# MSP432E401Y register map
Vendor: Texas Instruments; Series: MSP432E4; File version: 3.200
CPU: CM4 r1p2, little endian, no MPU, FPU, 3 interrupt priority bits
Registers are 32-bit, read-write, no defined reset value unless marked. A register's access mark holds for its fields unless they carry their own. Offsets are from the block's base; [hi:lo] are bit positions.

## SHAMD5_DMA — Register map for SHAMD5 DMA peripheral
Base 0x44030010; register names take the prefix SHAMD5_DMA
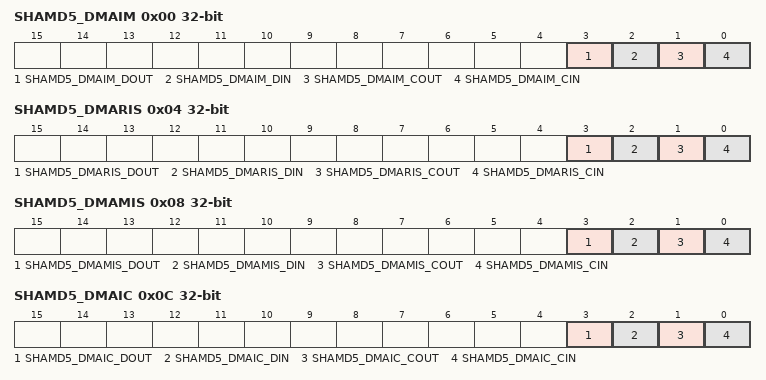
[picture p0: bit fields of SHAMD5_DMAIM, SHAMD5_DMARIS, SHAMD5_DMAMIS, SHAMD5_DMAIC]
0x00 SHAMD5_DMAIM — SHAMD5 DMA Interrupt Mask
  [3] SHAMD5_DMAIM_DOUT — Data Out DMA Done Interrupt Mask
  [2] SHAMD5_DMAIM_DIN — Data In DMA Done Interrupt Mask
  [1] SHAMD5_DMAIM_COUT — Context Out DMA Done Interrupt Mask
  [0] SHAMD5_DMAIM_CIN — Context In DMA Done Interrupt Mask
0x04 SHAMD5_DMARIS — SHAMD5 DMA Raw Interrupt Status
  [3] SHAMD5_DMARIS_DOUT — Data Out DMA Done Raw Interrupt Status
  [2] SHAMD5_DMARIS_DIN — Data In DMA Done Raw Interrupt Status
  [1] SHAMD5_DMARIS_COUT — Context Out DMA Done Raw Interrupt Status
  [0] SHAMD5_DMARIS_CIN — Context In DMA Done Raw Interrupt Status
0x08 SHAMD5_DMAMIS — SHAMD5 DMA Masked Interrupt Status
  [3] SHAMD5_DMAMIS_DOUT — Data Out DMA Done Masked Interrupt Status
  [2] SHAMD5_DMAMIS_DIN — Data In DMA Done Masked Interrupt Status
  [1] SHAMD5_DMAMIS_COUT — Context Out DMA Done Masked Interrupt Status
  [0] SHAMD5_DMAMIS_CIN — Context In DMA Done Masked Interrupt Status
0x0C SHAMD5_DMAIC — SHAMD5 DMA Interrupt Clear
  [3] SHAMD5_DMAIC_DOUT — Data Out DMA Done Interrupt Clear
  [2] SHAMD5_DMAIC_DIN — Data In DMA Done Interrupt Clear
  [1] SHAMD5_DMAIC_COUT — Context Out DMA Done Interrupt Clear
  [0] SHAMD5_DMAIC_CIN — Context In DMA Done Interrupt Clear

## AES_DMA — Register map for AES DMA peripheral
Base 0x44030020; register names take the prefix AES_DMA
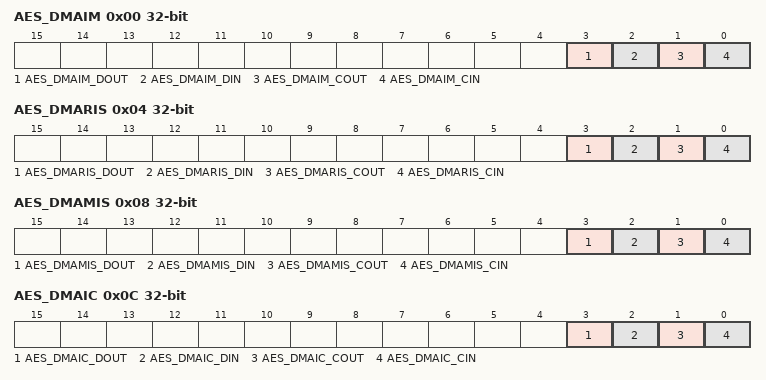
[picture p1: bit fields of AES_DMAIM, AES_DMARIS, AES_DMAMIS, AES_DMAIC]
0x00 AES_DMAIM — AES DMA Interrupt Mask
  [3] AES_DMAIM_DOUT — Data Out DMA Done Interrupt Mask
  [2] AES_DMAIM_DIN — Data In DMA Done Interrupt Mask
  [1] AES_DMAIM_COUT — Context Out DMA Done Interrupt Mask
  [0] AES_DMAIM_CIN — Context In DMA Done Interrupt Mask
0x04 AES_DMARIS — AES DMA Raw Interrupt Status
  [3] AES_DMARIS_DOUT — Data Out DMA Done Raw Interrupt Status
  [2] AES_DMARIS_DIN — Data In DMA Done Raw Interrupt Status
  [1] AES_DMARIS_COUT — Context Out DMA Done Raw Interrupt Status
  [0] AES_DMARIS_CIN — Context In DMA Done Raw Interrupt Status
0x08 AES_DMAMIS — AES DMA Masked Interrupt Status
  [3] AES_DMAMIS_DOUT — Data Out DMA Done Masked Interrupt Status
  [2] AES_DMAMIS_DIN — Data In DMA Done Masked Interrupt Status
  [1] AES_DMAMIS_COUT — Context Out DMA Done Masked Interrupt Status
  [0] AES_DMAMIS_CIN — Context In DMA Done Masked Interrupt Status
0x0C AES_DMAIC — AES DMA Interrupt Clear
  [3] AES_DMAIC_DOUT — Data Out DMA Done Interrupt Clear
  [2] AES_DMAIC_DIN — Data In DMA Done Interrupt Clear
  [1] AES_DMAIC_COUT — Context Out DMA Done Interrupt Clear
  [0] AES_DMAIC_CIN — Context In DMA Done Interrupt Clear

## DES — Register map for DES peripheral
Base 0x44038000; register names take the prefix DES
0x00 KEY3_L — DES Key 3 LSW for 192-Bit Key
  [31:0] DES_KEY3_L_KEY — Key Data
0x04 KEY3_H — DES Key 3 MSW for 192-Bit Key
  [31:0] DES_KEY3_H_KEY — Key Data
0x08 KEY2_L — DES Key 2 LSW for 128-Bit Key
  [31:0] DES_KEY2_L_KEY — Key Data
0x0C KEY2_H — DES Key 2 MSW for 128-Bit Key
  [31:0] DES_KEY2_H_KEY — Key Data
0x10 KEY1_L — DES Key 1 LSW for 64-Bit Key
  [31:0] DES_KEY1_L_KEY — Key Data
0x14 KEY1_H — DES Key 1 MSW for 64-Bit Key
  [31:0] DES_KEY1_H_KEY — Key Data
0x18 IV_L — DES Initialization Vector
  [31:0] DES_IV_L — Initialization vector for CBC, CFB modes (LSW)
0x1C IV_H — DES Initialization Vector
  [31:0] DES_IV_H — Initialization vector for CBC, CFB modes (MSW)
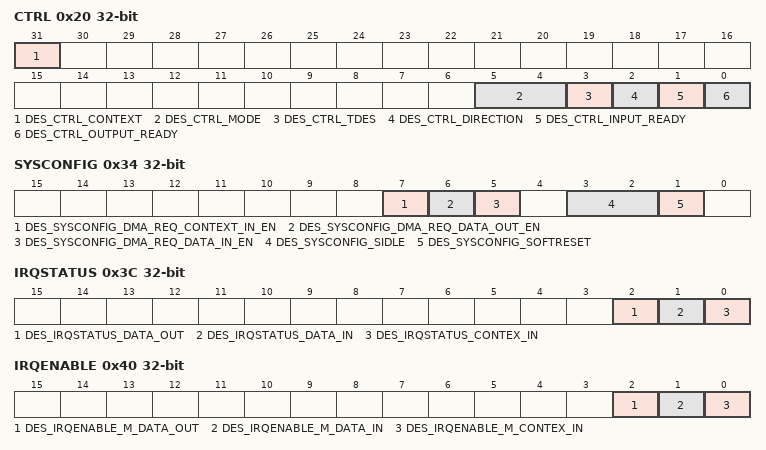
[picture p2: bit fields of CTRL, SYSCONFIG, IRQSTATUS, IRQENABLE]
0x20 CTRL — DES Control
  [31] DES_CTRL_CONTEXT — If 1, this read-only status bit indicates that the context data registers can be overwritten and the host is permitted to write the next context
  [5:4] DES_CTRL_MODE — Select CBC, ECB or CFB mode0x0: ECB mode0x1: CBC mode0x2: CFB mode0x3: reserved
  [3] DES_CTRL_TDES — Select DES or triple DES encryption/decryption
  [2] DES_CTRL_DIRECTION — Select encryption/decryption 0x0: decryption is selected0x1: Encryption is selected
  [1] DES_CTRL_INPUT_READY — When 1, ready to encrypt/decrypt data
  [0] DES_CTRL_OUTPUT_READY — When 1, Data decrypted/encrypted ready
0x24 LENGTH — DES Cryptographic Data Length
  [31:0] DES_LENGTH — Cryptographic data length in bytes for all modes
0x28 DATA_L — DES LSW Data RW
  [31:0] DES_DATA_L — Data for encryption/decryption, LSW
0x2C DATA_H — DES MSW Data RW
  [31:0] DES_DATA_H — Data for encryption/decryption, MSW
0x30 REVISION — DES Revision Number
  [31:0] DES_REVISION — Revision number
0x34 SYSCONFIG — DES System Configuration
  [7] DES_SYSCONFIG_DMA_REQ_CONTEXT_IN_EN — DMA Request Context In Enable
  [6] DES_SYSCONFIG_DMA_REQ_DATA_OUT_EN — DMA Request Data Out Enable
  [5] DES_SYSCONFIG_DMA_REQ_DATA_IN_EN — DMA Request Data In Enable
  [3:2] DES_SYSCONFIG_SIDLE — Sidle mode
    0=DES_SYSCONFIG_SIDLE_FORCE (Force-idle mode)
  [1] DES_SYSCONFIG_SOFTRESET — Soft reset
0x38 SYSSTATUS — DES System Status
  [0] DES_SYSSTATUS_RESETDONE — Reset Done
0x3C IRQSTATUS — DES Interrupt Status
  [2] DES_IRQSTATUS_DATA_OUT — This bit indicates data output interrupt is active and triggers the interrupt output
  [1] DES_IRQSTATUS_DATA_IN — This bit indicates data input interrupt is active and triggers the interrupt output
  [0] DES_IRQSTATUS_CONTEX_IN — This bit indicates context interrupt is active and triggers the interrupt output
0x40 IRQENABLE — DES Interrupt Enable
  [2] DES_IRQENABLE_M_DATA_OUT — If this bit is set to 1 the data output interrupt is enabled
  [1] DES_IRQENABLE_M_DATA_IN — If this bit is set to 1 the data input interrupt is enabled
  [0] DES_IRQENABLE_M_CONTEX_IN — If this bit is set to 1 the context interrupt is enabled
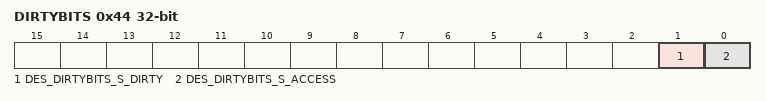
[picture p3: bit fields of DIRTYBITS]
0x44 DIRTYBITS — DES Dirty Bits
  [1] DES_DIRTYBITS_S_DIRTY — This bit is set to 1 by the module if any of the DES_* registers is written
  [0] DES_DIRTYBITS_S_ACCESS — This bit is set to 1 by the module if any of the DES_* registers is read

## DES_DMA — Register map for DES DMA peripheral
Base 0x44030030; register names take the prefix DES_DMA
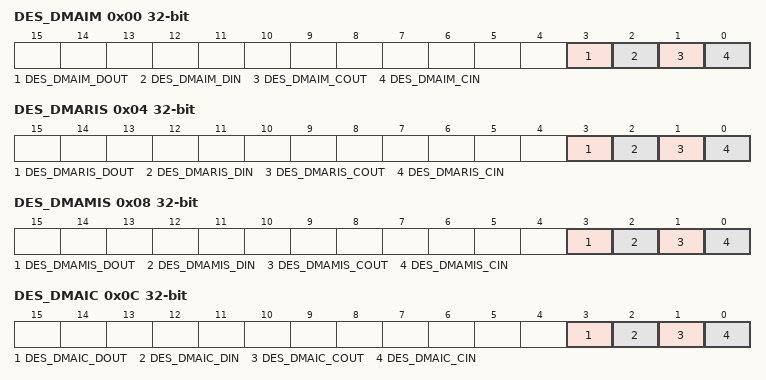
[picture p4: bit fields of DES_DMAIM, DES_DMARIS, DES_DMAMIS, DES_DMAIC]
0x00 DES_DMAIM — DES DMA Interrupt Mask
  [3] DES_DMAIM_DOUT — Data Out DMA Done Interrupt Mask
  [2] DES_DMAIM_DIN — Data In DMA Done Interrupt Mask
  [1] DES_DMAIM_COUT — Context Out DMA Done Interrupt Mask
  [0] DES_DMAIM_CIN — Context In DMA Done Interrupt Mask
0x04 DES_DMARIS — DES DMA Raw Interrupt Status
  [3] DES_DMARIS_DOUT — Data Out DMA Done Raw Interrupt Status
  [2] DES_DMARIS_DIN — Data In DMA Done Raw Interrupt Status
  [1] DES_DMARIS_COUT — Context Out DMA Done Raw Interrupt Status
  [0] DES_DMARIS_CIN — Context In DMA Done Raw Interrupt Status
0x08 DES_DMAMIS — DES DMA Masked Interrupt Status
  [3] DES_DMAMIS_DOUT — Data Out DMA Done Masked Interrupt Status
  [2] DES_DMAMIS_DIN — Data In DMA Done Masked Interrupt Status
  [1] DES_DMAMIS_COUT — Context Out DMA Done Masked Interrupt Status
  [0] DES_DMAMIS_CIN — Context In DMA Done Masked Interrupt Status
0x0C DES_DMAIC — DES DMA Interrupt Clear
  [3] DES_DMAIC_DOUT — Data Out DMA Done Interrupt Clear
  [2] DES_DMAIC_DIN — Data In DMA Done Interrupt Clear
  [1] DES_DMAIC_COUT — Context Out DMA Done Interrupt Clear
  [0] DES_DMAIC_CIN — Context In DMA Done Interrupt Clear
